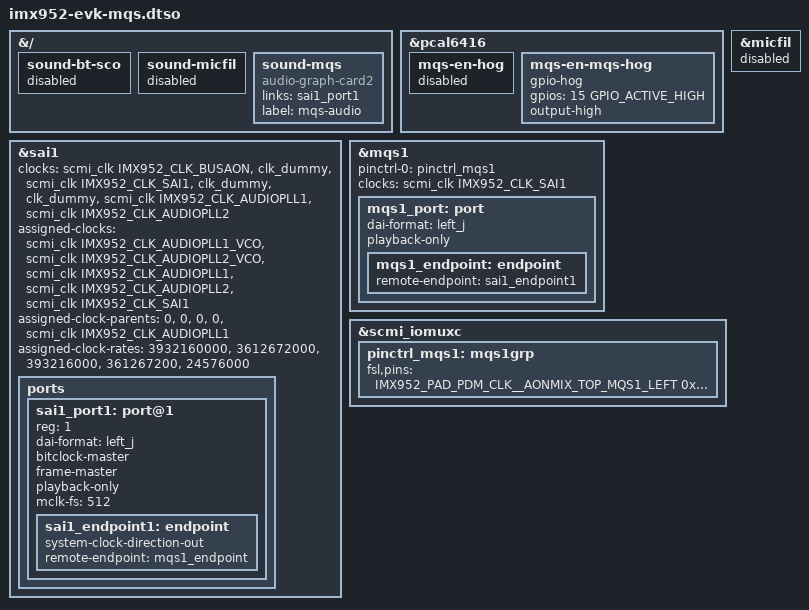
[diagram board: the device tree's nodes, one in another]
// SPDX-License-Identifier: (GPL-2.0+ OR MIT)
/*
 * Copyright 2026 NXP
 */

#include <dt-bindings/gpio/gpio.h>
#include "imx952-clock.h"
#include "imx952-pinfunc.h"

/dts-v1/;
/plugin/;

&{/} {
	sound-bt-sco {
		status = "disabled";
	};

	sound-micfil {
		status = "disabled";
	};

	sound-mqs {
		compatible = "audio-graph-card2";
		links = <&sai1_port1>;
		label = "mqs-audio";
	};
};

&pcal6416 {
	mqs-en-hog {
		status = "disabled";
	};

	mqs-en-mqs-hog {
		gpio-hog;
		gpios = <15 GPIO_ACTIVE_HIGH>;
		output-high;
	};
};

&sai1 {
	clocks = <&scmi_clk IMX952_CLK_BUSAON>, <&clk_dummy>,
		 <&scmi_clk IMX952_CLK_SAI1>, <&clk_dummy>,
		 <&clk_dummy>, <&scmi_clk IMX952_CLK_AUDIOPLL1>,
		 <&scmi_clk IMX952_CLK_AUDIOPLL2>;
	clock-names = "bus", "mclk0", "mclk1", "mclk2", "mclk3", "pll8k", "pll11k";
	assigned-clocks = <&scmi_clk IMX952_CLK_AUDIOPLL1_VCO>,
			  <&scmi_clk IMX952_CLK_AUDIOPLL2_VCO>,
			  <&scmi_clk IMX952_CLK_AUDIOPLL1>,
			  <&scmi_clk IMX952_CLK_AUDIOPLL2>,
			  <&scmi_clk IMX952_CLK_SAI1>;
	assigned-clock-parents = <0>, <0>, <0>, <0>,
				 <&scmi_clk IMX952_CLK_AUDIOPLL1>;
	assigned-clock-rates = <3932160000>, <3612672000>,
			       <393216000>, <361267200>, <24576000>;

	ports {
		#address-cells = <1>;
		#size-cells = <0>;

		sai1_port1: port@1 {
			reg = <1>;
			dai-format = "left_j";
			bitclock-master;
			frame-master;
			playback-only;
			mclk-fs = <512>;

			sai1_endpoint1: endpoint {
				system-clock-direction-out;
				remote-endpoint = <&mqs1_endpoint>;
			};
		};
	};
};

&mqs1 {
	pinctrl-names = "default";
	pinctrl-0 = <&pinctrl_mqs1>;
	clocks = <&scmi_clk IMX952_CLK_SAI1>;
	clock-names = "mclk";
	#sound-dai-cells = <0>;
	status = "okay";

	mqs1_port: port {
		dai-format = "left_j";
		playback-only;

		mqs1_endpoint: endpoint {
			remote-endpoint = <&sai1_endpoint1>;
		};
	};
};

&micfil {
	status = "disabled";
};

&scmi_iomuxc {
	pinctrl_mqs1: mqs1grp {
		fsl,pins = <
			IMX952_PAD_PDM_CLK__AONMIX_TOP_MQS1_LEFT		0x31e
			IMX952_PAD_PDM_BIT_STREAM0__AONMIX_TOP_MQS1_RIGHT	0x31e
		>;
	};
};
